VERSION "1.0"

NS_ :

BS_:

BU_: PedalECU DynamicsECU VCU

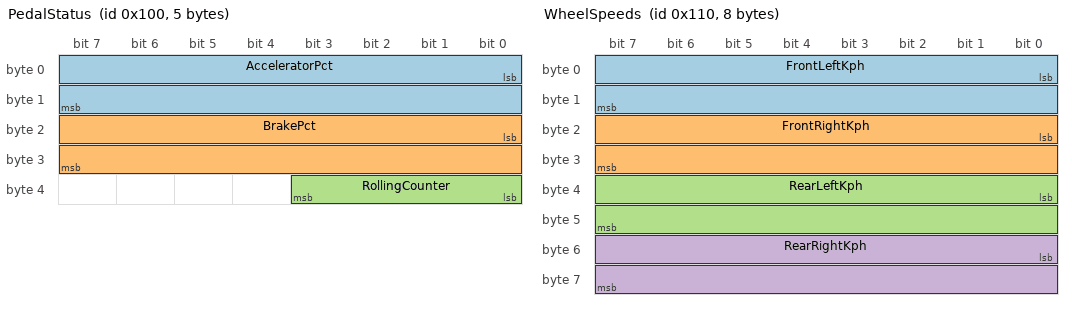
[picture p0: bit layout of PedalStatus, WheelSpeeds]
BO_ 256 PedalStatus: 5 PedalECU
 SG_ AcceleratorPct : 0|16@1+ (0.1,0) [0|100] "%" VCU
 SG_ BrakePct       : 16|16@1+ (0.1,0) [0|100] "%" VCU
 SG_ RollingCounter : 32|4@1+ (1,0) [0|15] "" VCU

BO_ 272 WheelSpeeds: 8 DynamicsECU
 SG_ FrontLeftKph   : 0|16@1+ (0.1,0) [0|6553.5] "km/h" VCU
 SG_ FrontRightKph  : 16|16@1+ (0.1,0) [0|6553.5] "km/h" VCU
 SG_ RearLeftKph    : 32|16@1+ (0.1,0) [0|6553.5] "km/h" VCU
 SG_ RearRightKph   : 48|16@1+ (0.1,0) [0|6553.5] "km/h" VCU

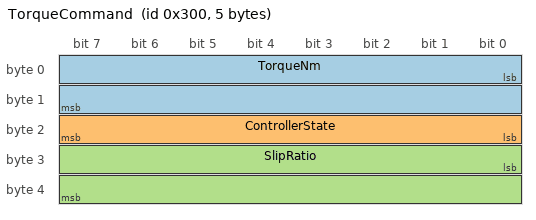
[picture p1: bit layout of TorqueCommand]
BO_ 768 TorqueCommand: 5 VCU
 SG_ TorqueNm        : 0|16@1- (0.1,0) [-3276.8|3276.7] "Nm" Vector__XXX
 SG_ ControllerState : 16|8@1+ (1,0) [0|2] "" Vector__XXX
 SG_ SlipRatio       : 24|16@1- (0.001,0) [-32.768|32.767] "" Vector__XXX

VAL_ 768 ControllerState 0 "READY" 1 "DERATE" 2 "FAULT" ;

CM_ BO_ 256 "Driver input message with 4-bit rolling counter.";
CM_ BO_ 272 "Four wheel speeds used by the traction-control calculation.";
CM_ BO_ 768 "VCU output torque request, controller state, and estimated driven-wheel slip.";
